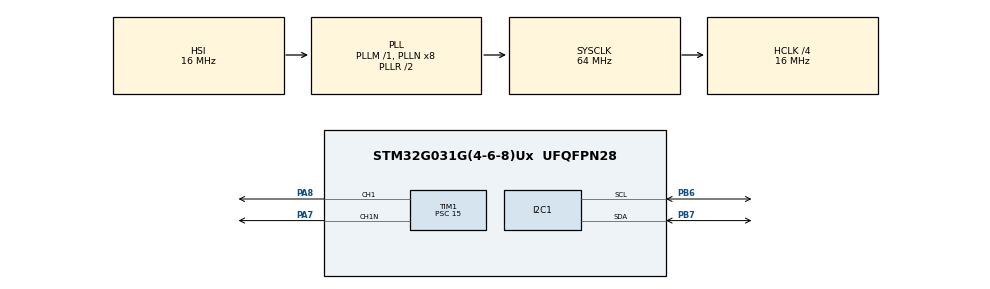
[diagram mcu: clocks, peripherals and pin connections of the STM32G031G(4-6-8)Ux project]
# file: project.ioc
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I2C1.Timing=0x00503D58
Mcu.Family=STM32G0
Mcu.Name=STM32G031G(4-6-8)Ux
Mcu.Package=UFQFPN28
NVIC.PVD_IRQn=true\:0\:0\:false\:false\:true\:true\:true\:true
PA13.Mode=Serial_Wire
PA13.Signal=SYS_SWDIO
PA14-BOOT0.Mode=Serial_Wire
PA14-BOOT0.Signal=SYS_SWCLK
PA7.Mode=PWM Generation1 CH1 CH1N
PA7.Signal=TIM1_CH1N
PA8.Signal=S_TIM1_CH1
PB6.Mode=I2C
PB6.Signal=I2C1_SCL
PB7.Mode=I2C
PB7.Signal=I2C1_SDA
ProjectManager.HeapSize=0x200
ProjectManager.StackSize=0x400
ProjectManager.TargetToolchain=CMake
RCC.ADCFreq_Value=64000000
RCC.AHBCLKDivider=RCC_SYSCLK_DIV4
RCC.AHBFreq_Value=16000000
RCC.CortexFreq_Value=16000000
RCC.EXTERNAL_CLOCK_VALUE=12288000
RCC.HCLKFreq_Value=16000000
RCC.HSE_VALUE=8000000
RCC.HSI_VALUE=16000000
RCC.LSE_VALUE=32768
RCC.SYSCLKFreq_VALUE=64000000
RCC.SYSCLKSource=RCC_SYSCLKSOURCE_PLLCLK
RCC.VCOOutputFreq_Value=128000000
SH.S_TIM1_CH1.0=TIM1_CH1,PWM Generation1 CH1 CH1N
SYS.Mode=PWR_PVD_MODE_IT_RISING_FALLING
SYS.PVDLevel=PWR_PVDLEVEL_4
TIM1.AutoReloadPreload=TIM_AUTORELOAD_PRELOAD_ENABLE
TIM1.AutomaticOutput=TIM_AUTOMATICOUTPUT_ENABLE
TIM1.Channel-PWM\ Generation1\ CH1\ CH1N=TIM_CHANNEL_1
TIM1.ClockDivision=TIM_CLOCKDIVISION_DIV1
TIM1.Period=999
TIM1.Prescaler=15
TIM1.Pulse-PWM\ Generation1\ CH1\ CH1N=500
VP_SYS_V_PVD_IN.Mode=Mode_PVD_Int
VP_TIM1_VS_ClockSourceINT.Mode=Internal
board=custom

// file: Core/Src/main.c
/* USER CODE BEGIN Header */
/**
  ******************************************************************************
  * @file    main.c
  * @brief   蜂鸣器驱动 + PVD 欠压保护 最终方案（无 RTC）
  ******************************************************************************
  */
/* USER CODE END Header */

#include "main.h"
#include "i2c.h"
#include "tim.h"
#include "buzzer_driver.h"
#include "music_data.h"

void SystemClock_Config(void);
static void MX_GPIO_Init(void);
static void PVD_UserInit(void); /* 手动 PVD，避免与 CubeMX pwr.c 冲突 */

/* USER CODE BEGIN 0 */

/**
 * @brief PVD 中断回调（上升沿/下降沿都会进）
 * @note  【必须放在 main() 外面，全局函数】
 */
void HAL_PWR_PVDCallback(void)
{
    if (__HAL_PWR_GET_FLAG(PWR_FLAG_PVDO))
    {
        /* 电压跌落至阈值以下 */
        Buzzer_PowerFault();
    }
    else
    {
        /* 电压回升至阈值以上 */
        Buzzer_PowerRecover();
    }
}

/* USER CODE END 0 */

int main(void)
{

  /* MCU Configuration--------------------------------------------------------*/

  /* Reset of all peripherals, Initializes the Flash interface and the Systick. */
  HAL_Init();

  /* Configure the system clock */
  SystemClock_Config();

  /* Initialize all configured peripherals */
  MX_GPIO_Init();
    /* 在 MX_I2C1_Init() 之后调用 */

  MX_I2C1_Init();
    NTAG_Dump();              // 先看当前状态
    NTAG_Init_ForPhoneWrite();// 写入 CC / 配置
    NTAG_Dump();              // 确认写进去了
  MX_TIM1_Init();
    /* MCU Configuration--------------------------------------------------------*//* CubeMX 生成的 TIM1 初始化 */
  Buzzer_Init();
  PVD_UserInit();            /* 使能 PVD 中断 */

    /* Infinite loop */
    while (1)
    {

        /* USER CODE BEGIN 3 */
        if (Buzzer_GetState() == BUZZER_FAULT)
        {
            /* 欠压中：进 STOP 苟命，等待 PVD 恢复中断唤醒 */
            HAL_SuspendTick();
            HAL_PWR_EnterSTOPMode(PWR_LOWPOWERREGULATOR_ON, PWR_STOPENTRY_WFI);
            HAL_ResumeTick();

            /* STOP 唤醒后默认切回 HSI，必须 restore 系统时钟 */
            SystemClock_Config();
        }
        else
        {
            /* 正常播放：内部每 1 ms 检测一次欠压标志，可被中断打断 */
            Buzzer_PlayMusic_Poll(music_score, MUSIC_LEN);
        }
        /* USER CODE END 3 */
    }
}

/* ============== 时钟配置（示例：HSI16 -> PLL -> 64 MHz）=============== */
void SystemClock_Config(void)
{
    RCC_OscInitTypeDef RCC_OscInitStruct = {0};
    RCC_ClkInitTypeDef RCC_ClkInitStruct = {0};

  /** Configure the main internal regulator output voltage
  */
  HAL_PWREx_ControlVoltageScaling(PWR_REGULATOR_VOLTAGE_SCALE1);

  /** Initializes the RCC Oscillators according to the specified parameters
  * in the RCC_OscInitTypeDef structure.
  */
  RCC_OscInitStruct.OscillatorType = RCC_OSCILLATORTYPE_HSI;
  RCC_OscInitStruct.HSIState = RCC_HSI_ON;
  RCC_OscInitStruct.HSIDiv = RCC_HSI_DIV1;
  RCC_OscInitStruct.HSICalibrationValue = RCC_HSICALIBRATION_DEFAULT;
  RCC_OscInitStruct.PLL.PLLState = RCC_PLL_ON;
  RCC_OscInitStruct.PLL.PLLSource = RCC_PLLSOURCE_HSI;
  RCC_OscInitStruct.PLL.PLLM = RCC_PLLM_DIV1;
  RCC_OscInitStruct.PLL.PLLN = 8;
  RCC_OscInitStruct.PLL.PLLP = RCC_PLLP_DIV2;
  RCC_OscInitStruct.PLL.PLLQ = RCC_PLLQ_DIV2;
  RCC_OscInitStruct.PLL.PLLR = RCC_PLLR_DIV2;
  if (HAL_RCC_OscConfig(&RCC_OscInitStruct) != HAL_OK)
  {
    Error_Handler();
  }

  /** Initializes the CPU, AHB and APB buses clocks
  */
  RCC_ClkInitStruct.ClockType = RCC_CLOCKTYPE_HCLK|RCC_CLOCKTYPE_SYSCLK
                              |RCC_CLOCKTYPE_PCLK1;
  RCC_ClkInitStruct.SYSCLKSource = RCC_SYSCLKSOURCE_PLLCLK;
  RCC_ClkInitStruct.AHBCLKDivider = RCC_SYSCLK_DIV4;
  RCC_ClkInitStruct.APB1CLKDivider = RCC_HCLK_DIV1;

  if (HAL_RCC_ClockConfig(&RCC_ClkInitStruct, FLASH_LATENCY_0) != HAL_OK)
  {
    Error_Handler();
  }
}

static void MX_GPIO_Init(void)
{
    /* USER CODE BEGIN MX_GPIO_Init_1 */
    /* 保留 CubeMX 为你生成的 MX_GPIO_Init() 全部代码。此处仅防止编译报错 */
    /* USER CODE END MX_GPIO_Init_1 */

    __HAL_RCC_GPIOA_CLK_ENABLE();
    /* 其它引脚配置由 CubeMX 生成 ... */

}

/* ============== PVD 手动初始化（避免与 CubeMX pwr.c 冲突）============= */
/**
  * @brief 手动配置 PVD（欠压/恢复双沿中断）
  * @note   如果你已经在 CubeMX 里 enable 了 PVD，请删掉本函数，
  *         并在 main() 中改为调用 CubeMX 生成的 MX_PVD_Init()。
  *         阈值请对照数据手册选择，G0 系列典型值如下（上升沿）：
  *           LEVEL_0 ≈ 2.0V | LEVEL_1 ≈ 2.2V | LEVEL_2 ≈ 2.4V
  *           LEVEL_3 ≈ 2.5V | LEVEL_4 ≈ 2.6V | LEVEL_5 ≈ 2.8V | LEVEL_6 ≈ 2.9V
  */
static void PVD_UserInit(void)
{
    PWR_PVDTypeDef sConfigPVD = {0};

    sConfigPVD.PVDLevel = PWR_PVDLEVEL_1;       /* 例：2.2V 档，按需求改 */
    sConfigPVD.Mode     = PWR_PVD_MODE_IT_RISING_FALLING;

    HAL_PWR_ConfigPVD(&sConfigPVD);
    HAL_PWR_EnablePVD();

    HAL_NVIC_SetPriority(PVD_IRQn, 2, 0);
    HAL_NVIC_EnableIRQ(PVD_IRQn);
}

/* ============== 错误处理 ============================================== */
void Error_Handler(void)
{
  __disable_irq();
  while (1) {
  }
}
